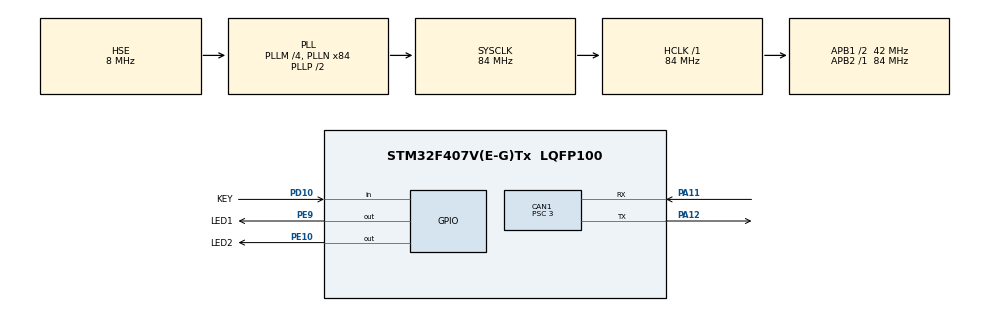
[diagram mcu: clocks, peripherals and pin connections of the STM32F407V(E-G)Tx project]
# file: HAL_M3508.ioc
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CAN1.BS1=CAN_BS1_9TQ
CAN1.BS2=CAN_BS2_4TQ
CAN1.CalculateBaudRate=1000000
CAN1.CalculateTimeBit=1000
CAN1.CalculateTimeQuantum=71.42857142857143
CAN1.Mode=CAN_MODE_NORMAL
CAN1.Prescaler=3
CAN1.TXFP=ENABLE
Mcu.Family=STM32F4
Mcu.Name=STM32F407V(E-G)Tx
Mcu.Package=LQFP100
NVIC.CAN1_RX0_IRQn=true\:1\:0\:true\:false\:true\:true\:true\:true
NVIC.CAN1_TX_IRQn=true\:1\:0\:true\:false\:true\:true\:true\:true
NVIC.PriorityGroup=NVIC_PRIORITYGROUP_4
NVIC.TIM6_DAC_IRQn=true\:15\:0\:false\:false\:true\:false\:true\:true
NVIC.TimeBase=TIM6_DAC_IRQn
NVIC.TimeBaseIP=TIM6
PA11.Mode=CAN_Activate
PA11.Signal=CAN1_RX
PA12.Mode=CAN_Activate
PA12.Signal=CAN1_TX
PA13.Mode=Serial_Wire
PA13.Signal=SYS_JTMS-SWDIO
PA14.Mode=Serial_Wire
PA14.Signal=SYS_JTCK-SWCLK
PC14-OSC32_IN.Mode=LSE-External-Oscillator
PC14-OSC32_IN.Signal=RCC_OSC32_IN
PC15-OSC32_OUT.Mode=LSE-External-Oscillator
PC15-OSC32_OUT.Signal=RCC_OSC32_OUT
PD10.GPIO_Label=KEY
PD10.Signal=GPIO_Input
PE10.GPIO_Label=LED2
PE10.GPIO_Speed=GPIO_SPEED_FREQ_HIGH
PE10.PinState=GPIO_PIN_SET
PE10.Signal=GPIO_Output
PE9.GPIO_Label=LED1
PE9.GPIO_Speed=GPIO_SPEED_FREQ_HIGH
PE9.PinState=GPIO_PIN_SET
PE9.Signal=GPIO_Output
PH0-OSC_IN.Mode=HSE-External-Oscillator
PH0-OSC_IN.Signal=RCC_OSC_IN
PH1-OSC_OUT.Mode=HSE-External-Oscillator
PH1-OSC_OUT.Signal=RCC_OSC_OUT
ProjectManager.HeapSize=0x200
ProjectManager.StackSize=0x400
ProjectManager.TargetToolchain=MDK-ARM V5.32
RCC.48MHZClocksFreq_Value=42000000
RCC.AHBFreq_Value=84000000
RCC.APB1CLKDivider=RCC_HCLK_DIV2
RCC.APB1Freq_Value=42000000
RCC.APB1TimFreq_Value=84000000
RCC.APB2Freq_Value=84000000
RCC.APB2TimFreq_Value=84000000
RCC.CortexFreq_Value=84000000
RCC.HCLKFreq_Value=84000000
RCC.HSE_VALUE=8000000
RCC.HSI_VALUE=16000000
RCC.PLLM=4
RCC.PLLN=84
RCC.PLLSourceVirtual=RCC_PLLSOURCE_HSE
RCC.SYSCLKFreq_VALUE=84000000
RCC.SYSCLKSource=RCC_SYSCLKSOURCE_PLLCLK
RCC.VCOOutputFreq_Value=168000000
VP_SYS_VS_tim6.Mode=TIM6
board=custom

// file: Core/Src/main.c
/* USER CODE BEGIN Header */
/**
  ******************************************************************************
  * @file           : main.c
  * @brief          : Main program body
  ******************************************************************************
  * @attention
  *
  * Copyright (c) 2023 STMicroelectronics.
  * All rights reserved.
  *
  * This software is licensed under terms that can be found in the LICENSE file
  * in the root directory of this software component.
  * If no LICENSE file comes with this software, it is provided AS-IS.
  *
  ******************************************************************************
  */
/* USER CODE END Header */
#include "main.h"
#include "can.h"
#include "gpio.h"
#include "user_can_init.h"
#include "pid.h"
#include "vesc_can.h"

void SystemClock_Config(void);

pid_type_def              motor_pid;      //声明PID数据结构体1
extern PID_TypeDef   Drive_Motor_Pid[4];  //声明PID数据结构体2

const motor_measure_t    *motor_data[4];  //声明电机结构体指针

int    set_speed = 0 ;                    //目标速度
const  fp32  PID[3] = { 10 ,0.02, 0};     //P,I,D

int main(void)
{

  /* MCU Configuration--------------------------------------------------------*/

  /* Reset of all peripherals, Initializes the Flash interface and the Systick. */
  HAL_Init();

  /* Configure the system clock */
  SystemClock_Config();

  /* Initialize all configured peripherals */
  MX_GPIO_Init();
  MX_CAN1_Init();
  /* USER CODE BEGIN 2 */

  User_Open_Can();
  VESC_t vesc;

  vesc.controller_id = 101;
  vesc.hcann = &hcan1;

  /* USER CODE END 2 */

  /* Infinite loop */
  /* USER CODE BEGIN WHILE */
  while (1)
  {
    can_send_command(&vesc, CAN_PACKET_SET_DUTY,0.5,1);
	  can_send_command(&vesc, CAN_PACKET_SET_CURRENT,1000,1);
    can_send_command(&vesc, CAN_PACKET_SET_RPM,1000,1);

    // comm_can_set_rpm(101,1000);
    // vesc_can_set_duty(101,0.5);

		HAL_Delay(2);

  }
}

void SystemClock_Config(void)
{
  RCC_OscInitTypeDef RCC_OscInitStruct = {0};
  RCC_ClkInitTypeDef RCC_ClkInitStruct = {0};

  /** Configure the main internal regulator output voltage
  */
  __HAL_RCC_PWR_CLK_ENABLE();
  __HAL_PWR_VOLTAGESCALING_CONFIG(PWR_REGULATOR_VOLTAGE_SCALE1);

  /** Initializes the RCC Oscillators according to the specified parameters
  * in the RCC_OscInitTypeDef structure.
  */
  RCC_OscInitStruct.OscillatorType = RCC_OSCILLATORTYPE_HSE;
  RCC_OscInitStruct.HSEState = RCC_HSE_ON;
  RCC_OscInitStruct.PLL.PLLState = RCC_PLL_ON;
  RCC_OscInitStruct.PLL.PLLSource = RCC_PLLSOURCE_HSE;
  RCC_OscInitStruct.PLL.PLLM = 4;
  RCC_OscInitStruct.PLL.PLLN = 84;
  RCC_OscInitStruct.PLL.PLLP = RCC_PLLP_DIV2;
  RCC_OscInitStruct.PLL.PLLQ = 4;
  if (HAL_RCC_OscConfig(&RCC_OscInitStruct) != HAL_OK)
  {
    Error_Handler();
  }

  /** Initializes the CPU, AHB and APB buses clocks
  */
  RCC_ClkInitStruct.ClockType = RCC_CLOCKTYPE_HCLK|RCC_CLOCKTYPE_SYSCLK
                              |RCC_CLOCKTYPE_PCLK1|RCC_CLOCKTYPE_PCLK2;
  RCC_ClkInitStruct.SYSCLKSource = RCC_SYSCLKSOURCE_PLLCLK;
  RCC_ClkInitStruct.AHBCLKDivider = RCC_SYSCLK_DIV1;
  RCC_ClkInitStruct.APB1CLKDivider = RCC_HCLK_DIV2;
  RCC_ClkInitStruct.APB2CLKDivider = RCC_HCLK_DIV1;

  if (HAL_RCC_ClockConfig(&RCC_ClkInitStruct, FLASH_LATENCY_2) != HAL_OK)
  {
    Error_Handler();
  }
}

void HAL_TIM_PeriodElapsedCallback(TIM_HandleTypeDef *htim)
{
  if (htim->Instance == TIM6) {
    HAL_IncTick();
  }
}

void Error_Handler(void)
{
  __disable_irq();
  while (1)
  {
  }
}
